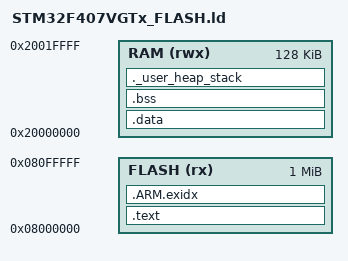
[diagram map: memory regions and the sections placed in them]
/* Linker script for STM32F407VGTx */

ENTRY(Reset_Handler)

MEMORY
{
  FLASH (rx) : ORIGIN = 0x08000000, LENGTH = 1024K
  RAM (rwx)  : ORIGIN = 0x20000000, LENGTH = 128K
}

_estack = ORIGIN(RAM) + LENGTH(RAM);

SECTIONS
{
  .text :
  {
    KEEP(*(.isr_vector))
    *(.text*)
    *(.rodata*)
    KEEP(*(.init))
    KEEP(*(.fini))
  } > FLASH

  .ARM.exidx :
  {
    *(.ARM.exidx*)
  } > FLASH

  .data : AT (ADDR(.text) + SIZEOF(.text))
  {
    *(.data*)
  } > RAM

  .bss :
  {
    *(.bss*)
    *(COMMON)
  } > RAM

  ._user_heap_stack :
  {
    . = ALIGN(8);
    PROVIDE(end = .);
    PROVIDE(_end = .);
    . = . + 0x400;  /* heap size */
    . = . + 0x1000; /* stack size */
  } > RAM
}
